# MK50DZ10 register map
Vendor: Freescale Semiconductor, Inc.; Series: Kinetis_K; File version: 1.6
CPU: CM4 r0p1, little endian, no MPU, no FPU, VTOR, 4 interrupt priority bits
Registers are 32-bit, read-write, reset 0x0 unless marked. A register's access mark holds for its fields unless they carry their own. Offsets are from the block's base; [hi:lo] are bit positions; {n}, {i} and the like mark numbered series.

## DAC0 — 12-Bit Digital-to-Analog Converter
Base 0x400CC000; register names take the prefix DAC0_
{0x0+2i} DAT{i}L (i=0..15) 8-bit — DAC Data Low Register
  [7:0] DATA
{0x1+2i} DAT{i}H (i=0..15) 8-bit — DAC Data High Register
  [3:0] DATA
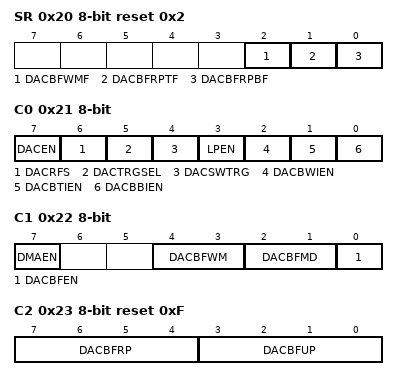
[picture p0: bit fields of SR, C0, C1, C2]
0x20 SR 8-bit reset 0x2 — DAC Status Register
  [2] DACBFWMF — DAC buffer watermark flag
    0=The DAC buffer read pointer has not reached the watermark level; 1=The DAC buffer read pointer has reached the watermark level
  [1] DACBFRPTF — DAC buffer read pointer top position flag
    0=The DAC buffer read pointer is not zero; 1=The DAC buffer read pointer is zero
  [0] DACBFRPBF — DAC buffer read pointer bottom position flag
    0=The DAC buffer read pointer is not equal to the DACBFUP; 1=The DAC buffer read pointer is equal to the DACBFUP
0x21 C0 8-bit — DAC Control Register
  [7] DACEN — DAC enable
    0=The DAC system is disabled; 1=The DAC system is enabled
  [6] DACRFS — DAC Reference Select
    0=The DAC selets DACREF_1 as the reference voltage; 1=The DAC selets DACREF_2 as the reference voltage
  [5] DACTRGSEL — DAC trigger select
    0=The DAC hardware trigger is selected; 1=The DAC software trigger is selected
  [4] DACSWTRG wo — DAC software trigger
    0=The DAC soft trigger is not valid; 1=The DAC soft trigger is valid
  [3] LPEN — DAC low power control
    0=high power mode; 1=low power mode
  [2] DACBWIEN — DAC buffer watermark interrupt enable
    0=The DAC buffer watermark interrupt is disabled; 1=The DAC buffer watermark interrupt is enabled
  [1] DACBTIEN — DAC buffer read pointer top flag interrupt enable
    0=The DAC buffer read pointer top flag interrupt is disabled; 1=The DAC buffer read pointer top flag interrupt is enabled
  [0] DACBBIEN — DAC buffer read pointer bottom flag interrupt enable
    0=The DAC buffer read pointer bottom flag interrupt is disabled; 1=The DAC buffer read pointer bottom flag interrupt is enabled
0x22 C1 8-bit — DAC Control Register 1
  [7] DMAEN — DMA enable select
    0=DMA disabled; 1=DMA enabled. When DMA enabled, DMA request will be generated by original interrupts. And interrupts will not be presented on this module at the same time.
  [4:3] DACBFWM — DAC buffer watermark select
    0=1 word; 1=2 words; 2=3 words; 3=4 words
  [2:1] DACBFMD — DAC buffer work mode select
    0=Normal Mode; 1=Swing Mode; 2=One-Time Scan Mode
  [0] DACBFEN — DAC buffer enable
    0=Buffer read pointer disabled. The converted data is always the first word of the buffer.; 1=Buffer read pointer enabled. The converted data is the word that the read pointer points to. It means converted data can be from any word of the buffer.
0x23 C2 8-bit reset 0xF — DAC Control Register 2
  [7:4] DACBFRP — DAC buffer read pointer
  [3:0] DACBFUP — DAC buffer upper limit

## DAC1 — 12-Bit Digital-to-Analog Converter
Base 0x400CD000; register names take the prefix DAC1_
Registers as DAC0.

## OPAMP0 — General Purpose Operational Amplifier
Base 0x400F5000; register names take the prefix OPAMP0_
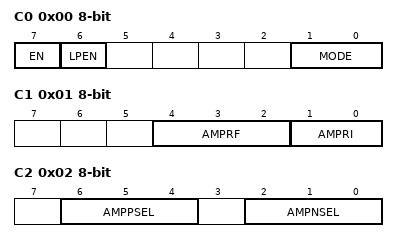
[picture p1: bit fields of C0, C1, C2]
0x00 C0 8-bit — Control Register 0
  [7] EN — OPAMP Enable
    0=OPAMP is disabled and not powered; 1=OPAMP is enabled and powered
  [6] LPEN — Low-Power Mode Enable
    0=High-speed mode selected. In this mode, OPAMP has faster slew rate and unity gain bandwidth performance with higher current consumption.; 1=Low-power mode selected. In this mode, OPAMP has lower current consumption with slower slew rate and unity gain bandwidth performance.
  [1:0] MODE — OPAMP Mode Select
    0=Buffer; 2=General purpose; 1=Inverting PGA; 3=Non-inverting PGA
0x01 C1 8-bit — Control Register 1
  [4:2] AMPRF — Gains Selector
  [1:0] AMPRI — Gains Selector
0x02 C2 8-bit — Control Register 2
  [6:4] AMPPSEL — Amplifier Positive Input Terminal Selector
    {v}=Positive input {v} (v=0..7)
  [2:0] AMPNSEL — Amplifier Negative Input Terminal Selector.
    {v}=Negative input {v} (v=0..7)

## OPAMP1 — General Purpose Operational Amplifier
Base 0x400F5800; register names take the prefix OPAMP1_
Registers as OPAMP0.

## Notices in the file
Redistribution and use in source and binary forms, with or without modification,
are permitted provided that the following conditions are met:
o Redistributions of source code must retain the above copyright notice, this list
of conditions and the following disclaimer.
o Redistributions in binary form must reproduce the above copyright notice, this
list of conditions and the following disclaimer in the documentation and/or
other materials provided with the distribution.
o Neither the name of Freescale Semiconductor, Inc. nor the names of its
contributors may be used to endorse or promote products derived from this
software without specific prior written permission.
THIS SOFTWARE IS PROVIDED BY THE COPYRIGHT HOLDERS AND CONTRIBUTORS "AS IS" AND
ANY EXPRESS OR IMPLIED WARRANTIES, INCLUDING, BUT NOT LIMITED TO, THE IMPLIED
WARRANTIES OF MERCHANTABILITY AND FITNESS FOR A PARTICULAR PURPOSE ARE
DISCLAIMED. IN NO EVENT SHALL THE COPYRIGHT HOLDER OR CONTRIBUTORS BE LIABLE FOR
ANY DIRECT, INDIRECT, INCIDENTAL, SPECIAL, EXEMPLARY, OR CONSEQUENTIAL DAMAGES
(INCLUDING, BUT NOT LIMITED TO, PROCUREMENT OF SUBSTITUTE GOODS OR SERVICES;
LOSS OF USE, DATA, OR PROFITS; OR BUSINESS INTERRUPTION) HOWEVER CAUSED AND ON
ANY THEORY OF LIABILITY, WHETHER IN CONTRACT, STRICT LIABILITY, OR TORT
(INCLUDING NEGLIGENCE OR OTHERWISE) ARISING IN ANY WAY OUT OF THE USE OF THIS
SOFTWARE, EVEN IF ADVISED OF THE POSSIBILITY OF SUCH DAMAGE.
